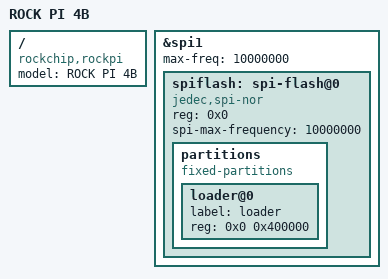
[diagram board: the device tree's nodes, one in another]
//This devicetree overlay is used to boot ROCK Pi 4 from SPI Flash device.
//Test device: GD25Q127CSIG
/dts-v1/;
/plugin/;

/ {
	model = "ROCK PI 4B";
	compatible = "rockchip,rockpi","rockchip,rk3399";

	fragment@0 {
		target = <&spi1>;

		__overlay__ {
			status = "okay";
			max-freq = <10000000>;
			#address-cells = <1>;
			#size-cells = <0>;

			spiflash: spi-flash@0 {
				#address-cells = <0x1>;
				#size-cells = <1>; 
				compatible = "jedec,spi-nor";
				reg = <0x0>;
				spi-max-frequency = <10000000>;
				status = "okay";

				partitions {
					compatible = "fixed-partitions";
					#address-cells = <1>;
					#size-cells = <1>;

					loader@0 {
						label = "loader";
						reg = <0x0 0x400000>;
					};
				};
			};
		};
	};
};
